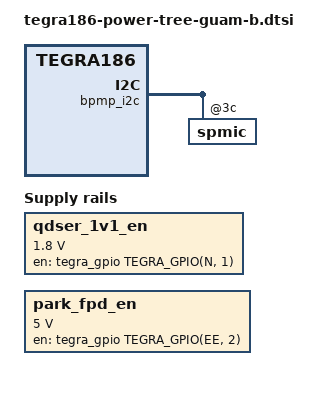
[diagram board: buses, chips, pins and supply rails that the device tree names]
/*
 * Copyright (c) 2016, NVIDIA CORPORATION.  All rights reserved.
 *
 * This program is free software; you can redistribute it and/or modify
 * it under the terms of the GNU General Public License as published by
 * the Free Software Foundation; either version 2 of the License, or
 * (at your option) any later version.
 *
 * This program is distributed in the hope that it will be useful, but WITHOUT
 * ANY WARRANTY; without even the implied warranty of MERCHANTABILITY or
 * FITNESS FOR A PARTICULAR PURPOSE.  See the GNU General Public License for
 * more details.
 */

#include "tegra186-platforms/tegra186-vcm31-power-tree-p2379-0000-c01-00.dtsi"

/ {

	/* using VBUS2_EN for USB2A */
	pinctrl@3520000 {
		/delete-property/ vbus-2-supply;
		vbus-0-supply = <&vdd_usb2_5v>;
	};

	/* Do not turn off LDO3, LDO3 is set to 1.8v in BCT PMIC */
	bpmp_i2c {
		spmic: spmic@3c {
			regulators {
				spmic_ldo3: ldo3 {
					regulator-always-on;
				};
			};
		};
	};

	fixed-regulators {

		/delete-node/regulator@5;
		/delete-node/regulator@6;

		qdser_1v1_en: regulator@9 {
			compatible = "regulator-fixed-sync";
			reg = <9>;
			regulator-name = "park-qdser-1v1-en";
			regulator-min-microvolt = <1800000>;
			regulator-max-microvolt = <1800000>;
			gpio = <&tegra_gpio TEGRA_GPIO(N, 1) 0>;
			enable-active-high;
			regulator-always-on;
		};
		park_fpd_en: regulator@12 {
			compatible = "regulator-fixed-sync";
			reg = <12>;
			regulator-name = "park-fpd-en";
			regulator-min-microvolt = <5000000>;
			regulator-max-microvolt = <5000000>;
			gpio = <&tegra_gpio TEGRA_GPIO(EE, 2) 0>;
			enable-active-high;
			regulator-always-on;
		};
	};
};
